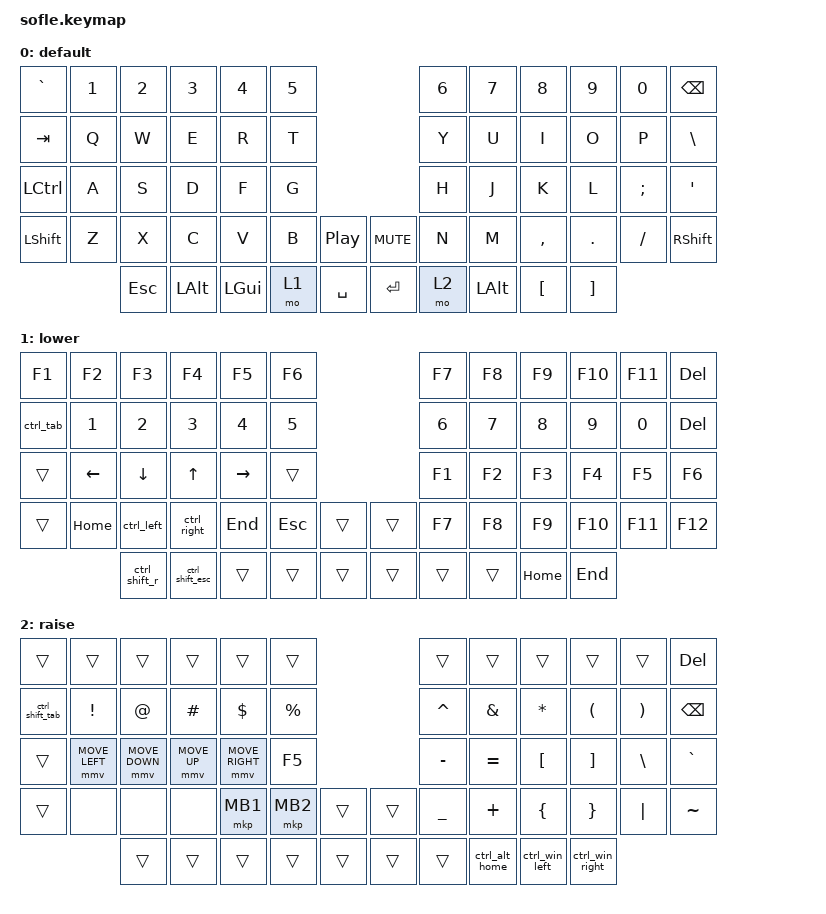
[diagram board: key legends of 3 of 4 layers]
/*
 * Copyright (c) 2020 The ZMK Contributors
 *
 * SPDX-License-Identifier: MIT
 */

#include <behaviors.dtsi>
#include <dt-bindings/zmk/keys.h>
#include <dt-bindings/zmk/bt.h>
#include <dt-bindings/zmk/rgb.h>
#include <dt-bindings/zmk/ext_power.h>
#include <dt-bindings/zmk/pointing.h>

#define ZMK_POINTING_DEFAULT_MOVE_VAL 1200  // default: 600
#define ZMK_POINTING_DEFAULT_SCRL_VAL 20

#define BASE 0
#define LOWER 1
#define RAISE 2
#define ADJUST 3

/ {
  macros {
    ctrl_alt_home: ctrl_alt_home {
      compatible = "zmk,behavior-macro";
      #binding-cells = <0>;
      bindings = <&macro_press &kp LCTRL &kp LALT>,
                  <&macro_tap &kp HOME>,
                  <&macro_release &kp LCTRL &kp LALT>;
    };
    ctrl_win_left: ctrl_win_left {
      compatible = "zmk,behavior-macro";
      #binding-cells = <0>;
      bindings = <&macro_press &kp LCTRL &kp LGUI>,
                  <&macro_tap &kp LEFT>,
                  <&macro_release &kp LCTRL &kp LGUI>;
    };
    ctrl_win_right: ctrl_win_right {
      compatible = "zmk,behavior-macro";
      #binding-cells = <0>;
      bindings = <&macro_press &kp LCTRL &kp LGUI>,
                  <&macro_tap &kp RIGHT>,
                  <&macro_release &kp LCTRL &kp LGUI>;
    };
    ctrl_shift_esc: ctrl_shift_esc {
      compatible = "zmk,behavior-macro";
      #binding-cells = <0>;
      bindings = <&macro_press &kp LCTRL &kp LSHIFT>,
                  <&macro_tap &kp ESC>,
                  <&macro_release &kp LCTRL &kp LSHIFT>;
    };
    alt_f4: alt_f4 {
      compatible = "zmk,behavior-macro";
      #binding-cells = <0>;
      bindings = <&macro_press &kp LALT>,
                  <&macro_tap &kp F4>,
                  <&macro_release &kp LALT>;
    };
    ctrl_shift_r: ctrl_shift_r {
      compatible = "zmk,behavior-macro";
      #binding-cells = <0>;
      bindings = <&macro_press &kp LCTRL &kp LSHIFT>,
                  <&macro_tap &kp R>,
                  <&macro_release &kp LCTRL &kp LSHIFT>;
    };
    win_l: win_l {
      compatible = "zmk,behavior-macro";
      #binding-cells = <0>;
      bindings = <&macro_press &kp LGUI>,
                  <&macro_tap &kp L>,
                  <&macro_release &kp LGUI>;
    };
    ctrl_left: ctrl_left {
      compatible = "zmk,behavior-macro";
      #binding-cells = <0>;
      bindings = <&macro_press &kp LCTRL>,
                  <&macro_tap &kp LEFT>,
                  <&macro_release &kp LCTRL>;
    };
    ctrl_right: ctrl_right {
      compatible = "zmk,behavior-macro";
      #binding-cells = <0>;
      bindings = <&macro_press &kp LCTRL>,
                  <&macro_tap &kp RIGHT>,
                  <&macro_release &kp LCTRL>;
    };
    ctrl_tab: ctrl_tab {
      compatible = "zmk,behavior-macro";
      #binding-cells = <0>;
      bindings = <&macro_press &kp LCTRL>,
                  <&macro_tap &kp TAB>,
                  <&macro_release &kp LCTRL>;
    };
    ctrl_shift_tab: ctrl_shift_tab {
      compatible = "zmk,behavior-macro";
      #binding-cells = <0>;
      bindings = <&macro_press &kp LCTRL &kp LSHIFT>,
                  <&macro_tap &kp TAB>,
                  <&macro_release &kp LCTRL &kp LSHIFT>;
    };
  };
};

/ {

   // Activate ADJUST layer by pressing raise and lower
    conditional_layers {
        compatible = "zmk,conditional-layers";
        adjust_layer {
            if-layers = <LOWER RAISE>;
            then-layer = <ADJUST>;
        };
    };

    keymap {
        compatible = "zmk,keymap";
        default_layer {
            display-name = "default";
            bindings = <
&kp GRAVE       &kp N1          &kp N2          &kp N3          &kp N4          &kp N5                                          &kp N6          &kp N7          &kp N8          &kp N9          &kp N0          &kp BSPC
&kp TAB         &kp Q           &kp W           &kp E           &kp R           &kp T                                           &kp Y           &kp U           &kp I           &kp O           &kp P           &kp BSLH
&kp LCTRL       &kp A           &kp S           &kp D           &kp F           &kp G                                           &kp H           &kp J           &kp K           &kp L           &kp SEMI        &kp SQT
&kp LSHFT       &kp Z           &kp X           &kp C           &kp V           &kp B           &kp C_PP        &kp C_MUTE      &kp N           &kp M           &kp COMMA       &kp DOT         &kp FSLH        &kp RSHFT
                                &kp ESC         &kp LALT        &kp LGUI        &mo 1           &kp SPACE       &kp RET         &mo 2           &kp LALT        &kp LBKT        &kp RBKT
            >;
            sensor-bindings = <&inc_dec_kp C_VOL_UP C_VOL_DN &inc_dec_kp PG_UP PG_DN>;
        };
        lower_layer {
            display-name = "lower";
            bindings = <
&kp F1          &kp F2          &kp F3          &kp F4          &kp F5          &kp F6                                          &kp F7          &kp F8          &kp F9          &kp F10         &kp F11        &kp DEL
&ctrl_tab       &kp N1          &kp N2          &kp N3          &kp N4          &kp N5                                          &kp N6          &kp N7          &kp N8          &kp N9          &kp N0          &kp DEL
&trans          &kp LEFT        &kp DOWN        &kp UP          &kp RIGHT       &trans                                          &kp F1          &kp F2          &kp F3          &kp F4          &kp F5          &kp F6
&trans          &kp HOME        &ctrl_left      &ctrl_right     &kp END         &kp ESC         &trans          &trans          &kp F7          &kp F8          &kp F9          &kp F10         &kp F11         &kp F12
                                &ctrl_shift_r   &ctrl_shift_esc &trans          &trans          &trans          &trans          &trans          &trans          &kp HOME        &kp END
            >;
            sensor-bindings = <&inc_dec_kp C_VOL_UP C_VOL_DN &inc_dec_kp PG_UP PG_DN>;
        };
        raise_layer {
            display-name = "raise";
            bindings = <
&trans          &trans          &trans          &trans          &trans          &trans                                          &trans          &trans          &trans          &trans          &trans          &kp DEL
&ctrl_shift_tab &kp EXCL        &kp AT          &kp HASH        &kp DLLR        &kp PRCNT                                       &kp CARET       &kp AMPS        &kp ASTRK       &kp LPAR        &kp RPAR       &kp BSPC
&trans          &mmv MOVE_LEFT  &mmv MOVE_DOWN  &mmv MOVE_UP    &mmv MOVE_RIGHT &kp F5                                          &kp MINUS       &kp EQUAL       &kp LBKT        &kp RBKT        &kp BSLH       &kp GRAVE
&trans          &none           &none           &none           &mkp MB1        &mkp MB2        &trans          &trans          &kp UNDER       &kp PLUS        &kp LBRC        &kp RBRC        &kp PIPE       &kp TILDE
                                &trans          &trans          &trans          &trans          &trans          &trans          &trans          &ctrl_alt_home  &ctrl_win_left  &ctrl_win_right
            >;
            sensor-bindings = <&inc_dec_kp C_VOL_UP C_VOL_DN &inc_dec_kp PG_UP PG_DN>;
        };
        adjust_layer {
            display-name = "adjust";
            bindings = <
&bt BT_SEL 0    &bt BT_SEL 1    &bt BT_SEL 2    &bt BT_SEL 3    &bt BT_SEL 4    &none                                           &soft_off       &none           &none           &none           &none           &bt BT_CLR 
&none           &rgb_ug RGB_HUD &rgb_ug RGB_HUI &rgb_ug RGB_SAD &rgb_ug RGB_SAI &rgb_ug RGB_EFF                                 &none           &none           &none           &none           &none           &ext_power EP_OFF
&none           &rgb_ug RGB_BRD &rgb_ug RGB_BRI &none           &none           &rgb_ug RGB_TOG                                 &kp PSCRN       &none           &none           &none           &none           &ext_power EP_TOG
&none           &none           &none           &none           &none           &none           &none           &none           &ctrl_alt_home  &ctrl_win_left  &ctrl_win_right &none           &none           &none
                                                &none           &none           &none           &bootloader     &bootloader     &none           &none           &none
            >;
            sensor-bindings = <&inc_dec_kp C_VOL_UP C_VOL_DN &inc_dec_kp PG_UP PG_DN>;
        };
    };
};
